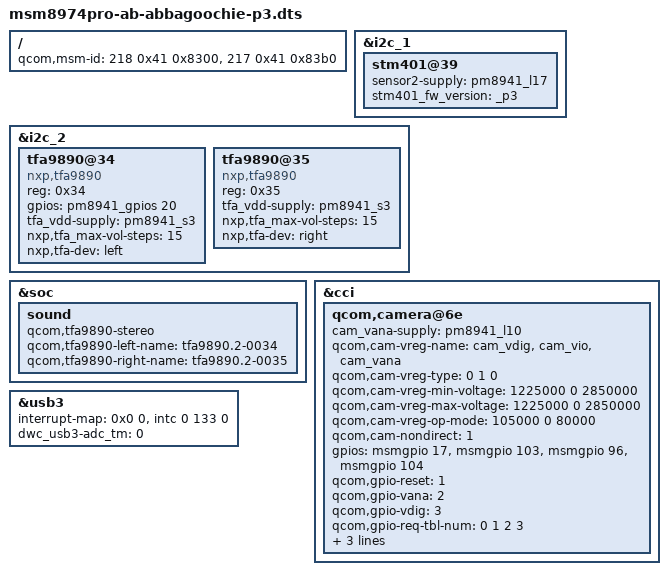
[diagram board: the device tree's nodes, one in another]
/* Copyright (c) 2013 Motorola Mobility LLC
 *
 * This program is free software; you can redistribute it and/or modify
 * it under the terms of the GNU General Public License version 2 and
 * only version 2 as published by the Free Software Foundation.
 *
 * This program is distributed in the hope that it will be useful,
 * but WITHOUT ANY WARRANTY; without even the implied warranty of
 * MERCHANTABILITY or FITNESS FOR A PARTICULAR PURPOSE.  See the
 * GNU General Public License for more details.
 */

/dts-v1/;
/include/ "msm8974pro-ab-moto-common.dtsi"
/include/ "msm8974pro-abbagoochie-common.dtsi"


/ {
	qcom,msm-id = <218 0x41 0x8300>,
		      <217 0x41 0x83b0>;
};

&i2c_1 {
        stm401@39 {
                sensor2-supply = <&pm8941_l17>;
		stm401_fw_version = "_p3";
        };
};


&i2c_2 {
	tfa9890@34 {
		compatible = "nxp,tfa9890";
		reg = <0x34>;
		gpios = <&pm8941_gpios 20 0>;     /* RESET */
		tfa_vdd-supply = <&pm8941_s3>;
		nxp,tfa_max-vol-steps = <15>;
		nxp,tfa-dev = "left";
	};

	tfa9890@35 {
		compatible = "nxp,tfa9890";
		reg = <0x35>;
		tfa_vdd-supply = <&pm8941_s3>;
		nxp,tfa_max-vol-steps = <15>;
		nxp,tfa-dev = "right";
	};
};

&soc {
	sound {
		qcom,tfa9890-stereo;
		qcom,tfa9890-left-name = "tfa9890.2-0034";
		qcom,tfa9890-right-name = "tfa9890.2-0035";
	};
};

&cci {

	qcom,camera@6e {
		cam_vana-supply = <&pm8941_l10>;
		qcom,cam-vreg-name = "cam_vdig", "cam_vio", "cam_vana";
		qcom,cam-vreg-type = <0 1 0>;
		qcom,cam-vreg-min-voltage = <1225000 0 2850000>;
		qcom,cam-vreg-max-voltage = <1225000 0 2850000>;
		qcom,cam-vreg-op-mode = <105000 0 80000>;
		qcom,cam-nondirect = <1>;  /* Abbagoochie p3 has to use Aptina dev board
                                      for Front camera */
		gpios = <&msmgpio 17 0>,
			<&msmgpio 103 0>,
			<&msmgpio 96 0>,
			<&msmgpio 104 0>;
		qcom,gpio-reset = <1>;
		qcom,gpio-vana = <2>;
		qcom,gpio-vdig = <3>;
		qcom,gpio-req-tbl-num = <0 1 2 3>;
		qcom,gpio-req-tbl-flags = <1 0 0 0>;
		qcom,gpio-req-tbl-label = "CAMIF_MCLK",
					  "CAM_RESET",
					  "CAM_AVDD",
					  "CAM_VDIG";
	};
};


&usb3 {
        interrupt-map = <0x0 0 &intc 0 133 0>;
        interrupt-names = "hs_phy_irq";
        dwc_usb3-adc_tm = <0>;
};
